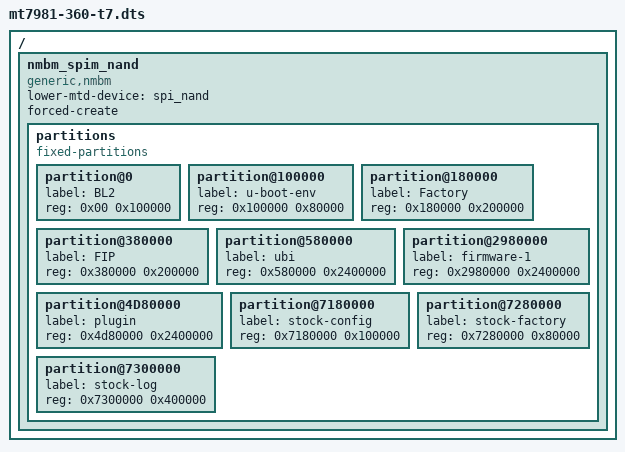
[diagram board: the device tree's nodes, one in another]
/dts-v1/;
#include "mt7981-360-t7-base.dtsi"

/ {
	nmbm_spim_nand {
		compatible = "generic,nmbm";

		#address-cells = <1>;
		#size-cells = <1>;

		lower-mtd-device = <&spi_nand>;
		forced-create;

		partitions {
			compatible = "fixed-partitions";
			#address-cells = <1>;
			#size-cells = <1>;

			partition@0 {
				label = "BL2";
				reg = <0x00 0x100000>;
			};

			partition@100000 {
				label = "u-boot-env";
				reg = <0x100000 0x80000>;
			};

			partition@180000 {
				label = "Factory";
				reg = <0x180000 0x200000>;
			};

			partition@380000 {
				label = "FIP";
				reg = <0x380000 0x200000>;
			};

			partition@580000 {
				label = "ubi";
				reg = <0x580000 0x2400000>;
			};

			partition@2980000 {
				label = "firmware-1";
				reg = <0x2980000 0x2400000>;
			};

			partition@4D80000 {
				label = "plugin";
				reg = <0x4d80000 0x2400000>;
			};

			partition@7180000 {
				label = "stock-config";
				reg = <0x7180000 0x100000>;
			};

			partition@7280000 {
				label = "stock-factory";
				reg = <0x7280000 0x80000>;
			};

			partition@7300000 {
				label = "stock-log";
				reg = <0x7300000 0x400000>;
			};
		};
	};
};
